# dm64lc_cslr_mcbsp_001 register map
Vendor: Texas Instruments
Peripheral module from a debugger description file.
Registers are 32-bit, read-write, reset 0x0 unless marked. A register's access mark holds for its fields unless they carry their own. Offsets are as the file gives them; lines under a group give offsets from that group; [hi:lo] are bit positions; {n}, {i} and the like mark numbered series; 'fields as' and 'values as' point back to an identical list; <NAME> marks a mode.

## MCBSP — Multi-Channel Buffered Serial Port
0x00 DRR ro — Data Receive Register
  [31:0] DRR — Data Receive Register(Read Only)
0x04 DXR — Data Transmit Register
  [31:0] DXR — Data Transmit Register(Read/Write)
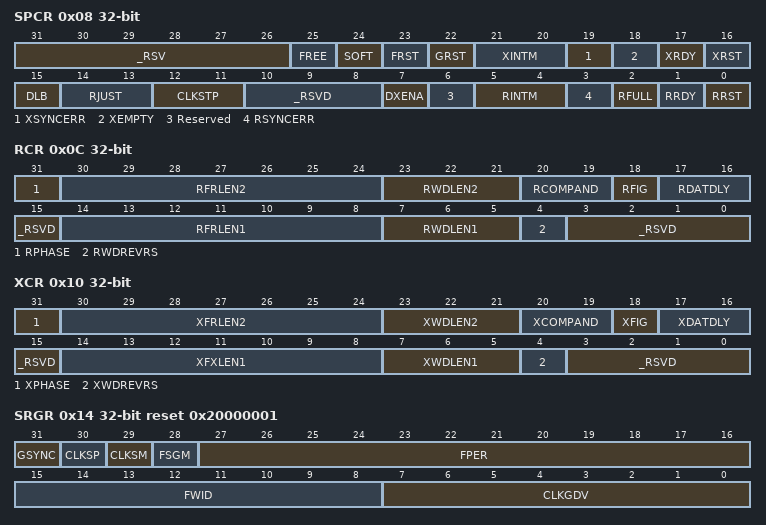
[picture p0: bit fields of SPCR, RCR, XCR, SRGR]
0x08 SPCR access not given — Serial Port Control Register
  [31:26] _RSV ro — These bits are not used
  [25] FREE rw — Controls Free running during emulation mode
    0=NO (Free Running Mode Disabled); 1=YES (Free Running Mode Enabled)
  [24] SOFT rw — Controls the emulation while the FREE bit is set
    0=NO (Soft Running Mode Disabled); 1=YES (Soft Running Mode Enabled)
  [23] FRST rw — Controls the Frame Sync Generator Reset
    0=RESET (Frame Sync Generator is in Reset); 1=FSG (Frame Sync Generator is out of Reset)
  [22] GRST rw — Controls the Sample Rate Generator Reset
    0=RESET (Sample Rate generator is in Reset); 1=CLKG (Sample Rate generator is out of Reset)
  [21:20] XINTM rw — Transmit Interrupt Mode
  [19] XSYNCERR rw — Transmit Synchronization Error
    0=NO (no synchronization error); 1=YES (synchronization error detected by McBSP.)
  [18] XEMPTY ro — Transmit Shift Register (XSR) Empty
    0=YES (XSR is empty); 1=NO (XSR Iis not Empty)
  [17] XRDY ro — Transmitter Ready
    0=NO (Transmitter is not ready); 1=YES (Transmitter is ready with data in DXR)
  [16] XRST rw — Transmitter Resets and enables the Transmitter
    0=DISABLE (Transmitter is disabled and in reset state); 1=ENABLE (Transmitter is enabled)
  [15] DLB rw — Sets Digital Loop Back Mode
    0=OFF (Digital loop back mode disabled); 1=ON (Digital loop back mode enabled)
  [14:13] RJUST rw — Enables Receive Sign-Extension and Justification Mode
  [12:11] CLKSTP rw — Enables Clock Stop Mode for SPI mode.
  [10:8] _RSVD — These bits are not used (access N)
  [7] DXENA rw — Enables extra delay for turn-on time.
    0=OFF (DX enabler is off); 1=ON (DX enabler is on)
  [6] Reserved — (access N)
  [5:4] RINTM rw — Receive Interrupt Mode
  [3] RSYNCERR rw — Receive Synchronization Error
    values as XSYNCERR
  [2] RFULL ro — Receive Shift Register (RSR) Empty
    0=NO (XSR is empty); 1=YES (XSR Iis not Empty)
  [1] RRDY ro — Receiver Ready
    values as XRDY
  [0] RRST rw — Receiver Reses and enables the Receiver
    values as XRST
0x0C RCR access not given — Receive Control Register
  [31] RPHASE rw — Receive Phase
    0=YES; 1=NO
  [30:24] RFRLEN2 rw — Receive Frame Length 2
  [23:21] RWDLEN2 rw — Receive Word Length 2
  [20:19] RCOMPAND rw — Receive Companding Mode.
  [18] RFIG rw — Receive Frame Ignore
    0=YES; 1=NO
  [17:16] RDATDLY rw — Receive data delay
  [15] _RSVD — These bits are not used(always cleared) (access N)
  [14:8] RFRLEN1 rw — Receive Frame Length 1
  [7:5] RWDLEN1 rw — Receive Word Length 1
  [4] RWDREVRS rw — Receive 32-bit reversal feature.
    0=DISABLED; 1=ENABLED
  [3:0] _RSVD — These bits are not used(always cleared) (access N)
0x10 XCR access not given — Transmit Control Register
  [31] XPHASE rw — Transmit Phase
    0=YES; 1=NO
  [30:24] XFRLEN2 rw — Transmit Frame Length 2
  [23:21] XWDLEN2 rw — Transmit Word Length 2
  [20:19] XCOMPAND rw — Transmit Companding Mode.
  [18] XFIG rw — Transmit Frame Ignore
    0=YES; 1=NO
  [17:16] XDATDLY rw — Transmit data delay
  [15] _RSVD — These bits are not used(always cleared) (access N)
  [14:8] XFXLEN1 rw — Transmit Frame Length 1
  [7:5] XWDLEN1 rw — Transmit Word Length 1
  [4] XWDREVRS rw — Transmit 32-bit reversal feature.
    0=DISABLED; 1=ENABLED
  [3:0] _RSVD — These bits are not used(always cleared) (access N)
0x14 SRGR reset 0x20000001 — Sample Rate Generator Register
  [31] GSYNC — Sample rate generator clock synchronization. Only used when the external clock (CLKS) drives the sample rate generator clock (CLKSM=0).
    0=FREE; 1=SYNC
  [30] CLKSP — CLKS Polarity Clock Edge Select. Only used when the external clock CLKS drives the sample rate generator clock (CLKSM=0).
    0=RISING; 1=FALLING
  [29] CLKSM — McBSP Sample Rate Generator Clock Mode
    0=CLKS; 1=INTERNAL
  [28] FSGM — Sample Rate Generator Transmit frame synchronization mode. Used when FSXM=1 in PCR.
    0=DXR2XSR; 1=FSG
  [27:16] FPER — Frame Period. This determines when the next frame sync signal should become active. Range: up to 212 ; 1 to 4096 CLKG periods.
  [15:8] FWID — Frame Width. Determines the width of the frame sync pulse, FSG, during its active period. Range: up to 28 ; 1 to 256 CLKG periods.
  [7:0] CLKGDV — Sample rate generator clock divider. This value is used as the divide-down number to generate the required sample rate generator clock frequency. Default value is 1.
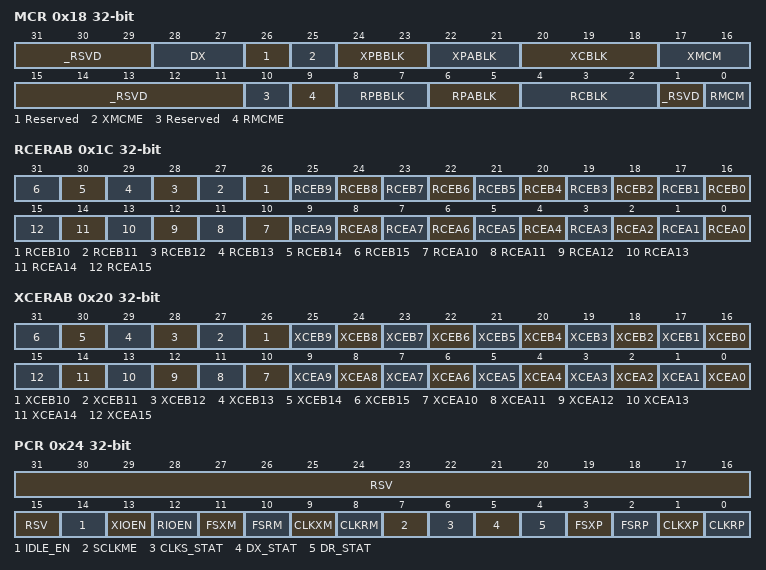
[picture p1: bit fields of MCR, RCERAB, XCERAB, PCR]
0x18 MCR access not given — Multi-Channel Register
  [31:29] _RSVD — (access N)
  [28:27] DX rw
  [26] Reserved — (access N)
  [25] XMCME rw
    0=_AtoB; 1=_AtoH
  [24:23] XPBBLK rw
  [22:21] XPABLK rw
  [20:18] XCBLK ro
  [17:16] XMCM rw
  [15:11] _RSVD — (access N)
  [10] Reserved — (access N)
  [9] RMCME rw
    0=_AtoB; 1=_AtoH
  [8:7] RPBBLK rw
  [6:5] RPABLK rw
  [4:2] RCBLK ro
  [1] _RSVD — (access N)
  [0] RMCM rw
    0=CHENABLE; 1=CHDISABLE
0x1C RCERAB — Receive Channel Enable Register Partition A/B (XCER(A/B)) registers are used to enable any of the 32 channels for receive
  [all] fields
    0=CHDISABLE; 1=CHENABLE
  [n+16] RCEB{n} (n=0..15)
  [n] RCEA{n} (n=0..15)
0x20 XCERAB — Transmit Channel Enable Register Partition A/B (XCER(A/B)) registers are used to enable any of the 32 channels for transmit
  [all] fields
    0=CHDISABLE; 1=CHENABLE
  [n+16] XCEB{n} (n=0..15)
  [n] XCEA{n} (n=0..15)
0x24 PCR access per field — Pin Control Register
  [31:15] RSV ro — These bits are not used(always cleared)
  [14] IDLE_EN rw — Idle enable bit for the McBSP
    0=RESET (The McBSP remains active when the PERIPH domain is idled.); 1=ON (If the PERIPH domain is idle (PERIS = 1 in the idle status register), the McBSP is stopped in a low-power state.)
  [13] XIOEN rw — Transmit General Purpose I/O Mode ONLY when XRST=0 in SPCR
    0=SP (The CLKX, FSX, DX, and CLKS pins are serial port pins.); 1=GPIO (If XRST = 0, the CLKX, FSX, and DX pins are GPIO pins. The CLKS is also a GPIO pin if RRST = 0 and RIOEN = 1.)
  [12] RIOEN rw — Receive General Purpose I/O Mode ONLY when RRST=0 in SPCR
    0=SP (The CLKR, FSR, DR, and CLKS pins are serial port pins.); 1=GPIO (If RRST = 0, the CLKR, FSR, and DR pins are GPIO pins. The CLKS is also a GPIO pin if XRST = 0 and XIOEN = 1.)
  [11] FSXM rw — Transmit Frame Synchronization Mode
    0=EXTERNAL (Transmit frame synchronization is supplied by an external source via the FSX pin.); 1=INTERNAL (Transmit frame synchronization is supplied by the McBSP, as determined by the FSGM bit of SRGR2.)
  [10] FSRM rw — Receive Frame Synchronization Mode
    0=EXTERNAL (Receive frame synchronization is supplied by an external source via the FSR pin.); 1=INTERNAL (Receive frame synchronization is supplied by the sample rate generator FSR is an output pin reflecting internal FSR, except when GSYNC = 1 in SRGR2.)
  [9] CLKXM rw — Transmitter Clock Mode.
    0=INPUT; 1=OUTPUT
  [8] CLKRM rw — Receiver Clock Mode
    0=INPUT; 1=OUTPUT
  [7] SCLKME rw — Enhanced sample clock mode selection bit.
    0=NO; 1=BCLK
  [6] CLKS_STAT ro — CLKS pin status. Reflects value on CLKS pin when selected as a general purpose input.
  [5] DX_STAT rw — DX pin status. Reflects value driven on to DX pin when selected as a general purpose output.
  [4] DR_STAT ro — DR pin status. Reflects value on DR pin when selected as a general purpose input.
  [3] FSXP rw — Transmit Frame Synchronization Polarity
    0=ACTIVEHIGH; 1=ACTIVELOW
  [2] FSRP rw — Receive Frame Synchronization Polarity
    0=ACTIVEHIGH; 1=ACTIVELOW
  [1] CLKXP rw — Transmit Clock Polarity
    0=RISING; 1=FALLING
  [0] CLKRP rw — Receive Clock Polarity
    0=FALLING; 1=RISING
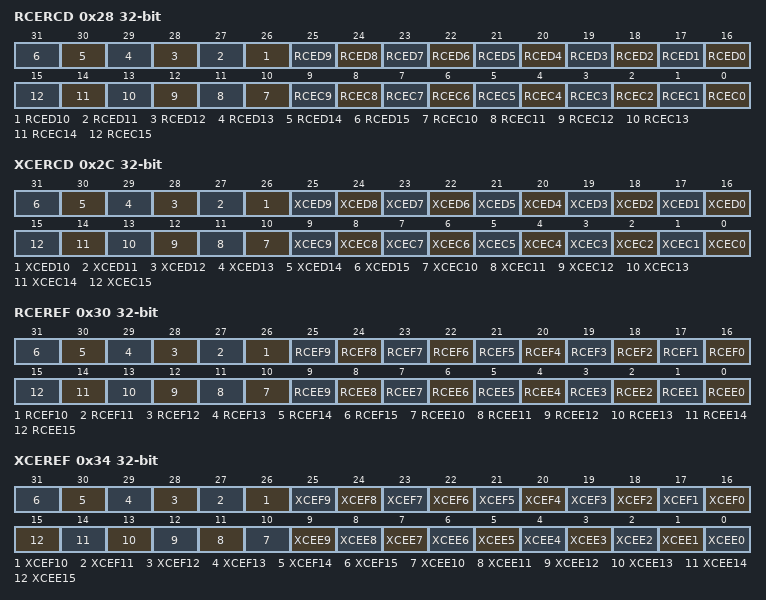
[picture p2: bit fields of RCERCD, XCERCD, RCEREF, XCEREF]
0x28 RCERCD — Receive Channel Enable Register Partition C/D
  [all] fields
    0=CHDISABLE; 1=CHENABLE
  [n+16] RCED{n} (n=0..15)
  [n] RCEC{n} (n=0..15)
0x2C XCERCD — Transmit Channel Enable Register Partition C/D
  [all] fields
    0=CHDISABLE; 1=CHENABLE
  [n+16] XCED{n} (n=0..15)
  [n] XCEC{n} (n=0..15)
0x30 RCEREF — Receive Channel Enable Register Partition E/F
  [all] fields
    0=CHDISABLE; 1=CHENABLE
  [n+16] RCEF{n} (n=0..15)
  [n] RCEE{n} (n=0..15)
0x34 XCEREF — Transmit Channel Enable Register Partition E/F
  [n+16] XCEF{n} (n=0..15)
    0=CHDISABLE; 1=CHENABLE
  [n] XCEE{n} (n=1..15)
    0=CHDISABLE; 1=CHENABLE
  [0] XCEE0
    0=CHDISABLE
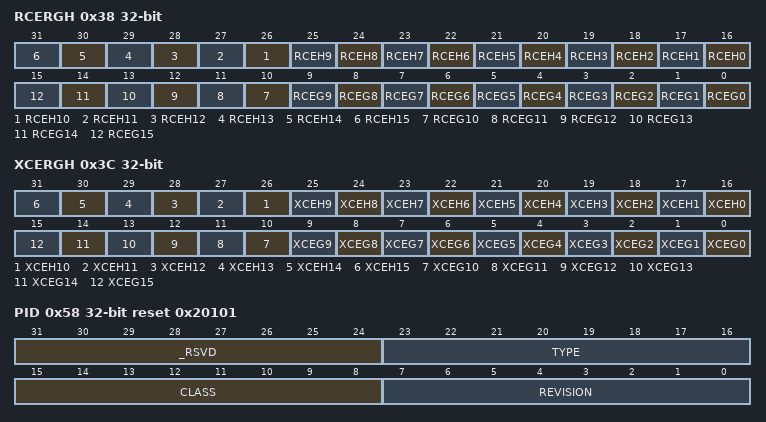
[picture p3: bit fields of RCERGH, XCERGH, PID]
0x38 RCERGH — Receive Channel Enable Register Partition G/H
  [all] fields
    0=CHDISABLE; 1=CHENABLE
  [n+16] RCEH{n} (n=0..15)
  [n] RCEG{n} (n=0..15)
0x3C XCERGH — Transmit Channel Enable Register Partition G/H
  [all] fields
    0=CHDISABLE; 1=CHENABLE
  [n+16] XCEH{n} (n=0..15)
  [n] XCEG{n} (n=0..15)
0x58 PID access not given reset 0x20101 — Peripheral ID Register
  [31:24] _RSVD — (access N)
  [23:16] TYPE ro — Identifes the Type of peripheral. This value should be 0x02
  [15:8] CLASS ro — Identifs the class of the McBSP512 peripheral. The value shall be 0x01
  [7:0] REVISION ro — Identifies the revision level of the McBSP512. This value shall begin at 0x01, and be incremented each time the design is revised.
